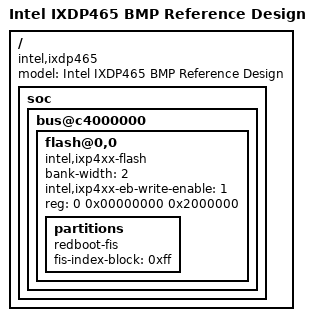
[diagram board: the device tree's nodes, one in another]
/dts-v1/;
#include "intel-ixp45x-ixp46x.dtsi"
#include "intel-ixp4xx-reference-design.dtsi"
#include <dt-bindings/input/input.h>
/ {
	model = "Intel IXDP465 BMP Reference Design";
	compatible = "intel,ixdp465", "intel,ixp46x";
	#address-cells = <1>;
	#size-cells = <1>;
	soc {
		bus@c4000000 {
			flash@0,0 {
				compatible = "intel,ixp4xx-flash", "cfi-flash";
				bank-width = <2>;
				intel,ixp4xx-eb-write-enable = <1>;
				reg = <0 0x00000000 0x2000000>;
				partitions {
					compatible = "redboot-fis";
					fis-index-block = <0xff>;
				};
			};
		};
	};
};
